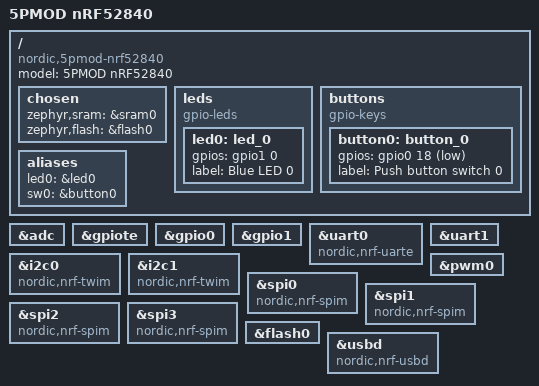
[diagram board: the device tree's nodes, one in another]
/* 
 * 5PMOD nRF52840 pinout
 * 
 * Power connector GPIO: P0.29A*
 * Addressable RGB LED: P0.08
 * Discrete LED: P1.00
 *
 * Pin#  PMOD1    PMOD2    PMOD3    PMOD4    PMOD5  
 *  1    P0.28A*  P0.30A*  P0.05A   P0.03A*  P0.02A*
 *  2    P1.08    P0.12    P0.19    P0.15    P0.24
 *  3    P0.11    P1.09    P0.21    P0.14    P0.20
 *  4    P0.25    P0.07    P0.23    P0.22    P0.17
 *  5    GND      GND      GND      GND      GND
 *  6    VCC      VCC      VCC      VCC      VCC
 *  7    P1.10*   P0.06    P0.16    P1.14*   P1.06*
 *  8    P1.15*   P0.26    P0.13    P1.02*   P1.04*
 *  9    P1.13*   P0.04A   P1.05*   P1.01*   P1.07*
 *  10   P1.11*   P0.31*   P0.27    P1.03*   P1.12*
 *  11   GND      GND      GND      GND      GND
 *  12   VCC      VCC      VCC      VCC      VCC
 *
 * PMODx-1: CS/CTS/_
 * PMODx-2: MOSI/TXD/_
 * PMODx-3: MISO/RXD/SCL
 * PMODx-4: SCK/RTS/SDA
 *
 * More details here:
 * https://reference.digilentinc.com/_media/reference/pmod/pmod-interface-specification-1_3_1.pdf
 */

/dts-v1/;
#include <nordic/nrf52840_qiaa.dtsi>

/* 
 * All available device tree nodes can be found in
 * zephyr/dts/arm/nordic/nrf52840.dtsi 
 */

/ {
	model = "5PMOD nRF52840";
	compatible = "nordic,5pmod-nrf52840";

	chosen {
		// zephyr,console = &uart0;
		// zephyr,shell-uart = &uart0;
		// zephyr,uart-mcumgr = &uart0;
		// zephyr,bt-mon-uart = &uart0;
		// zephyr,bt-c2h-uart = &uart0;
		zephyr,sram = &sram0;
		zephyr,flash = &flash0;
		// zephyr,code-partition = &slot0_partition;
	};

	leds {
		compatible = "gpio-leds";
		led0: led_0 {
			gpios = <&gpio1 0 0>;
			label = "Blue LED 0";
		};
	};

	/* Set Kconfig option 'CONFIG_GPIO_AS_PINRESET=n' to use button as input */
	buttons {
		compatible = "gpio-keys";
		button0: button_0 {
			gpios = <&gpio0 18 (GPIO_PULL_UP | GPIO_ACTIVE_LOW)>;
			label = "Push button switch 0";
		};
	};

	// TODO: Add WS2812 RGB LED

	// TODO: Add PMOD connector pinouts

	/* These aliases are provided for compatibility with samples */
	aliases {
		led0 = &led0;
		sw0 = &button0;
	};
};

&adc {
	status = "okay";
};

&gpiote {
	status = "okay";
};

&gpio0 {
	status = "okay";
};

&gpio1 {
	status = "okay";
};

&uart0 {
	compatible = "nordic,nrf-uarte";
	// status = "okay";
	// current-speed = <115200>;
	// tx-pin = <6>;
	// rx-pin = <8>;
	// rts-pin = <5>;
	// cts-pin = <7>;
};

&uart1 {
	// status = "okay";
	// current-speed = <115200>;
	// rx-pin = <33>;
	// tx-pin = <34>;
};

&i2c0 {
	compatible = "nordic,nrf-twim";
	/* Cannot be used together with spi0 */
	// status = "okay";
	// sda-pin = <26>;
	// scl-pin = <27>;
};

&i2c1 {
	compatible = "nordic,nrf-twim";
	/* Cannot be used together with spi1 */
	// status = "okay";
	// sda-pin = <30>;
	// scl-pin = <31>;
};

&pwm0 {
	// status = "okay";
	// ch0-pin = <13>;
	// ch0-inverted;
};

&spi0 {
	compatible = "nordic,nrf-spim";
	/* Cannot be used together with i2c0 */
	// status = "okay";
	// sck-pin = <27>;
	// mosi-pin = <26>;
	// miso-pin = <29>;
};

&spi1 {
	compatible = "nordic,nrf-spim";
	/* Cannot be used together with i2c1 */
	// status = "okay";
	// sck-pin = <31>;
	// mosi-pin = <30>;
	// miso-pin = <40>;
};

&spi2 {
	compatible = "nordic,nrf-spim";
	// status = "disabled";
	// sck-pin = <19>;
	// mosi-pin = <20>;
	// miso-pin = <21>;
};


&spi3 {
	compatible = "nordic,nrf-spim";
	// status = "okay";
	// sck-pin = <47>;
	// miso-pin = <46>;
	// mosi-pin = <45>;
	// cs-gpios = <&gpio0 16 GPIO_ACTIVE_LOW>;
};

&flash0 {
	/*
	 * For more information, see:
	 * http://docs.zephyrproject.org/latest/guides/dts/index.html#flash-partitions
	 */
	// partitions {
	// 	compatible = "fixed-partitions";
	// 	#address-cells = <1>;
	// 	#size-cells = <1>;

	// 	boot_partition: partition@0 {
	// 		label = "mcuboot";
	// 		reg = <0x000000000 0x0000C000>;
	// 	};
	// 	slot0_partition: partition@c000 {
	// 		label = "image-0";
	// 		reg = <0x0000C000 0x00067000>;
	// 	};
	// 	slot1_partition: partition@73000 {
	// 		label = "image-1";
	// 		reg = <0x00073000 0x00067000>;
	// 	};
	// 	scratch_partition: partition@da000 {
	// 		label = "image-scratch";
	// 		reg = <0x000da000 0x0001e000>;
	// 	};

	// 	/*
	// 	 * The flash starting at 0x000f8000 and ending at
	// 	 * 0x000fffff is reserved for use by the application.
	// 	 */

	// 	/*
	// 	 * Storage partition will be used by FCB/LittleFS/NVS
	// 	 * if enabled.
	// 	 */
	// 	storage_partition: partition@f8000 {
	// 		label = "storage";
	// 		reg = <0x000f8000 0x00008000>;
	// 	};
	// };
};

&usbd {
	compatible = "nordic,nrf-usbd";
	// status = "okay";
};
